# CH564 register map
Vendor: WCH Ltd.; File version: 1.0
Registers are 8-bit, read-write, reset 0x0 unless marked. A register's access mark holds for its fields unless they carry their own. Offsets are from the block's base; [hi:lo] are bit positions.

## USBHS_HOST — USBHS Host mode functions' registers
Base 0x40404800
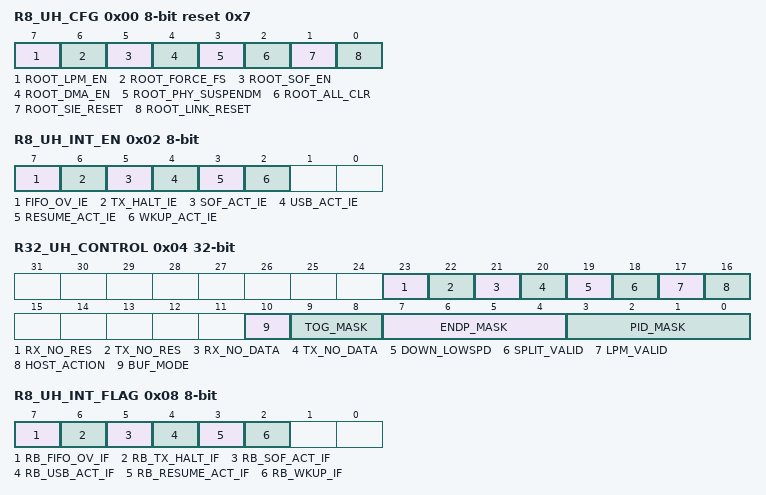
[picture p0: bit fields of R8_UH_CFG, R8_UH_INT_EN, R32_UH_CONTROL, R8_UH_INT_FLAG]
0x00 R8_UH_CFG reset 0x7 — USB host Configuration register
  [7] ROOT_LPM_EN — LPM enable
  [6] ROOT_FORCE_FS — forced full speed FS
  [5] ROOT_SOF_EN — sof packet sending function enabled
  [4] ROOT_DMA_EN — DMA transfer enabled
  [3] ROOT_PHY_SUSPENDM — PHY suspend,close utmi clock
  [2] ROOT_ALL_CLR — clear all interrupt flags
  [1] ROOT_SIE_RESET — USB protocol processor reset
  [0] ROOT_LINK_RESET — USB connection controller module resets
0x02 R8_UH_INT_EN — USB host interrupt enable register
  [7] FIFO_OV_IE — FIFO overflow interrupt enable
  [6] TX_HALT_IE — send pause interrupt enable
  [5] SOF_ACT_IE — sof packet sending interruption is enabled
  [4] USB_ACT_IE — USB transfer end interrupt enabled
  [3] RESUME_ACT_IE — bus recovery interrupt was enabled
  [2] WKUP_ACT_IE — Wakeup interrupt enabled
0x03 R8_UH_DEV_ADDR — USB host device address register
  [7:0] DEV_ADDR — device address
0x04 R32_UH_CONTROL 32-bit — USB host control register
  [23] RX_NO_RES — IN-DATA no answer,used for synchronous transfer or high-speed SPLIT packets
  [22] TX_NO_RES — OUT or SETUP DATA no reply is extended and is used for synchronous transmission or hign-speed SPLIT packets
  [21] RX_NO_DATA — DATA packets are not expected after IN token packets and are used for high-speed SPLIT packets
  [20] TX_NO_DATA — OUT or SETUP token packet packets are followed by no data packets for hign-speed SPLIT packets
  [19] DOWN_LOWSPD — this bit is enabled when the port is operating at full speed and needs to send low speed packets(PRE)
  [18] SPLIT_VALID — valid to send SPLIT packet
  [17] LPM_VALID — valid to send LMP packet
  [16] HOST_ACTION — host enables the transaction
  [10] BUF_MODE — DATA cache control bit
  [9:8] TOG_MASK — send data PID
  [7:4] ENDP_MASK — transaction token packet endpoint number
  [3:0] PID_MASK — transaction token packet PID
0x08 R8_UH_INT_FLAG — USB HOST interrupt flag register
  [7] RB_FIFO_OV_IF — FIFO overflow interrupt flag
  [6] RB_TX_HALT_IF — send pause interrupt flag
  [5] RB_SOF_ACT_IF — sof packet delivert completion interrupt flag
  [4] RB_USB_ACT_IF — USB transaction transfer completion interrupt flag
  [3] RB_RESUME_ACT_IF — bus recovery interrupt flag
  [2] RB_WKUP_IF — Wakeup interrupt flag
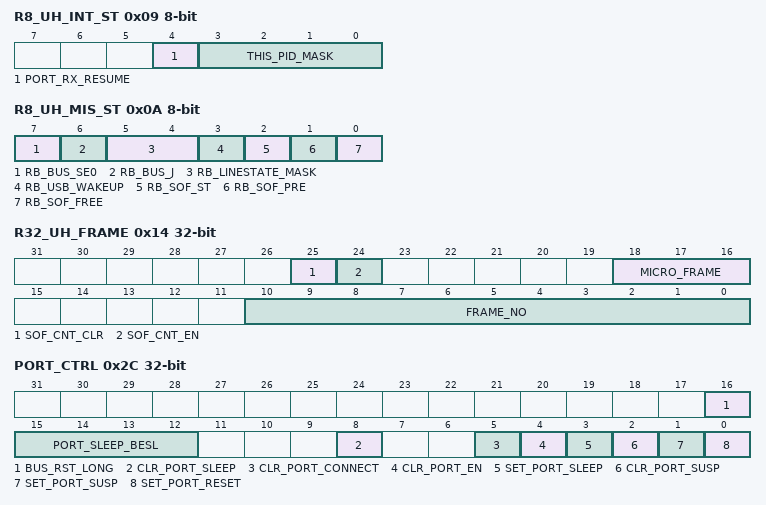
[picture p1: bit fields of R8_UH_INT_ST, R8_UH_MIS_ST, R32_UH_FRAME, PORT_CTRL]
0x09 R8_UH_INT_ST ro — USB host interrupt status
  [4] PORT_RX_RESUME — A bit of indicates that the port received a wakeup signal
  [3:0] THIS_PID_MASK — received PID
0x0A R8_UH_MIS_ST access per field — USB host miscellaneous status
  [7] RB_BUS_SE0 ro — SE0 on USB bus
  [6] RB_BUS_J rw — J on USB bus
  [5:4] RB_LINESTATE_MASK ro — USB bus status
  [3] RB_USB_WAKEUP rw — USB bus wakes up
  [2] RB_SOF_ST rw — USB bus SOF status
  [1] RB_SOF_PRE ro — The state of the USB SOF packet is indicated as follows
  [0] RB_SOF_FREE ro — port enabled state
0x0C R32_UH_LPM 32-bit — USB host power management data register
  [10:0] LPM_DATA — power management data
0x10 R32_UH_SPLIT 32-bit — USB host SPLIT register
  [18:0] SPLIT_DATA — SPLIT management data
0x14 R32_UH_FRAME 32-bit access per field — USB host frame register
  [25] SOF_CNT_CLR rw — the SOF count is cleared
  [24] SOF_CNT_EN rw — SOF count enabled
  [18:16] MICRO_FRAME ro — microfame number
  [10:0] FRAME_NO rw — the frame number
0x18 R32_UH_TX_LEN 32-bit — USB host send length register
  [10:0] TX_LEN — send data length
0x1C R32_UH_RX_LEN 32-bit — USB host receive length register
  [10:0] RX_LEN — Received data length
0x20 R32_UH_RX_MAX_LEN 32-bit — USB host receives the maximum length register
  [10:0] UH_RX_MAX_LEN — receives the maximum length
0x24 R32_UH_RX_DMA 32-bit — DMA receive address register
  [16:0] R16_UH_RX_DMA — Received address
0x28 R32_UH_TX_DMA 32-bit — DMA send address register
  [16:0] R16_UH_TX_DMA — Send address
0x2C PORT_CTRL 32-bit access per field — USB host port control register
  [16] BUS_RST_LONG rw — BUS reset time selection
  [15:12] PORT_SLEEP_BESL rw — wake-up time control
  [8] CLR_PORT_SLEEP wo — the PORT exits the sleep state (LPM)
  [5] CLR_PORT_CONNECT wo — bring the PORT into the port state
  [4] CLR_PORT_EN wo — PORT exits the enabled state and enters the DISABLED state
  [3] SET_PORT_SLEEP wo — the PORT goes to sleep(LPM)
  [2] CLR_PORT_SUSP wo — the PORT exits the suspended state
  [1] SET_PORT_SUSP wo — the PORT is in a suspended state
  [0] SET_PORT_RESET wo — PORT send reset
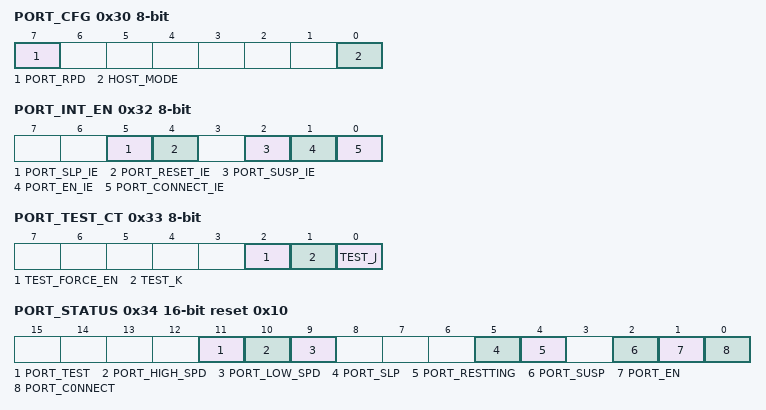
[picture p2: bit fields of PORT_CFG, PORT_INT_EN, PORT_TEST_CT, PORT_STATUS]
0x30 PORT_CFG — USB host port Configuration register
  [7] PORT_RPD — the 15k resistance drop-down function is enable in host mode
  [0] HOST_MODE — USB port mode selection
0x32 PORT_INT_EN — USB host port interrupt enable register
  [5] PORT_SLP_IE — port sleep state change interrupt enabled
  [4] PORT_RESET_IE — port reset state change interrupt enabled
  [2] PORT_SUSP_IE — port pause state change interrupt enabled
  [1] PORT_EN_IE — port enable state change interrupt enabled
  [0] PORT_CONNECT_IE — port connection state change interrupt enabled
0x33 PORT_TEST_CT — USB host port test mode register
  [2] TEST_FORCE_EN — test mode was enabled
  [1] TEST_K — test output K
  [0] TEST_J — test output J
0x34 PORT_STATUS 16-bit ro reset 0x10 — USB host port status register
  [11] PORT_TEST — whether the port is in test mode
  [10] PORT_HIGH_SPD — whether the port connection speed is hign
  [9] PORT_LOW_SPD — whether the port connection speed is low
  [5] PORT_SLP — port sleep
  [4] PORT_RESTTING — port reset status
  [2] PORT_SUSP — port pause state
  [1] PORT_EN — port enabled
  [0] PORT_C0NNECT — port connection state
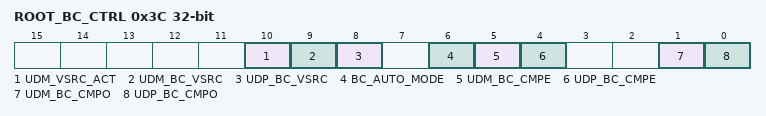
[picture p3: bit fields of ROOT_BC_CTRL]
0x3C ROOT_BC_CTRL 32-bit access per field — USB host BC charging control register
  [10] UDM_VSRC_ACT ro — In automatic mode, UDP outputs VBC_SRC ,otherwise it is controlled by UDM_BC_CMPE
  [9] UDM_BC_VSRC rw — UDM pin BC protocol source voltage enabled
  [8] UDP_BC_VSRC rw — UDP pin BC protocol source voltage enabled
  [6] BC_AUTO_MODE rw — Automatic mode enables
  [5] UDM_BC_CMPE rw — UDM pin BC protocol comparator enables
  [4] UDP_BC_CMPE rw — UDP pin BC protocol comparator enables
  [1] UDM_BC_CMPO ro — UDM pin BC protocol comparator status
  [0] UDP_BC_CMPO ro — UDP pin BC protocol comparator status
